# LargeDummyDevice register map
File version: 1.0
Registers are 32-bit, read-write, no defined reset value unless marked. A register's access mark holds for its fields unless they carry their own. Offsets are from the block's base; [hi:lo] are bit positions.

## PERIPHERAL_63
Base 0x4003E000
0x04 REG_1 — Register 1
  [29] FIELD_5, [29:28] FIELD_1, [22] FIELD_2, [17] FIELD_6, [14:10] FIELD_4, [9] FIELD_3
0x08 REG_2 — Register 2
  [32:31] FIELD_25, [30] FIELD_13, [29:27] FIELD_14, [27:26] FIELD_9, [29:26] FIELD_10, [25] FIELD_22, [24] FIELD_2, [27:24] FIELD_5, [28:24] FIELD_12, [25:24] FIELD_24, [24:23] FIELD_18, [22:21] FIELD_7, [25:21] FIELD_8, [25:21] FIELD_15, [22:21] FIELD_23, [21:19] FIELD_21, [18] FIELD_29, [19:18] FIELD_32, [20:16] FIELD_3, [18:16] FIELD_17, [19:15] FIELD_11, [12] FIELD_4, [12] FIELD_19, [11] FIELD_16, [12:11] FIELD_26, [13:10] FIELD_30, [13:10] FIELD_31, [11:7] FIELD_27, [10:6] FIELD_20, [9:5] FIELD_28, [8:4] FIELD_1, [4:0] FIELD_6
0x0C REG_3 — Register 3
  [30:29] FIELD_4, [33:29] FIELD_12, [24] FIELD_2, [21:19] FIELD_5, [20:19] FIELD_15, [18:17] FIELD_9, [19:15] FIELD_8, [18:14] FIELD_13, [17:13] FIELD_14, [13:9] FIELD_10, [8:7] FIELD_3, [9:6] FIELD_1, [7:5] FIELD_11, [3:2] FIELD_6, [4:1] FIELD_7
0x10 REG_4 — Register 4
  [25] FIELD_1, [23] FIELD_2, [16:13] FIELD_3, [6] FIELD_5, [7:3] FIELD_4
0x14 REG_5 — Register 5
  [26:25] FIELD_14, [19] FIELD_3, [21:17] FIELD_5, [16] FIELD_15, [17:15] FIELD_8, [15:14] FIELD_10, [15:14] FIELD_13, [15:11] FIELD_2, [14:10] FIELD_4, [12:10] FIELD_6, [14:10] FIELD_7, [8:7] FIELD_16, [8:4] FIELD_12, [5:3] FIELD_9, [4:1] FIELD_11, [3:0] FIELD_1
0x18 REG_6 — Register 6
  [29] FIELD_13, [29:27] FIELD_8, [27:26] FIELD_6, [28:25] FIELD_11, [25:24] FIELD_1, [21:20] FIELD_9, [18:14] FIELD_2, [6] FIELD_3, [9:6] FIELD_5, [6:4] FIELD_10, [6:4] FIELD_12, [5:3] FIELD_15, [6:2] FIELD_7, [3:1] FIELD_4, [2:0] FIELD_14
0x1C REG_7 — Register 7
  [32:31] FIELD_22, [34:30] FIELD_6, [32:30] FIELD_25, [28:25] FIELD_15, [28:24] FIELD_27, [26:23] FIELD_18, [25:23] FIELD_19, [24:22] FIELD_4, [23:20] FIELD_10, [20:18] FIELD_11, [18] FIELD_20, [18:17] FIELD_5, [17] FIELD_28, [18:14] FIELD_1, [16:14] FIELD_2, [16:13] FIELD_3, [12] FIELD_12, [15:12] FIELD_24, [14:12] FIELD_26, [13:11] FIELD_8, [14:10] FIELD_14, [13:10] FIELD_21, [7] FIELD_7, [6] FIELD_9, [8:6] FIELD_29, [9:5] FIELD_17, [4:2] FIELD_13, [2] FIELD_23, [4:2] FIELD_30, [3:0] FIELD_16
0x20 REG_8 — Register 8
  [35:31] FIELD_6, [31:29] FIELD_4, [32:28] FIELD_9, [25] FIELD_20, [26:24] FIELD_18, [20] FIELD_3, [19:18] FIELD_5, [20:18] FIELD_8, [18] FIELD_17, [19:15] FIELD_16, [12:11] FIELD_11, [13:11] FIELD_21, [12:10] FIELD_2, [8:7] FIELD_14, [10:6] FIELD_12, [7:6] FIELD_13, [4] FIELD_19, [5:3] FIELD_10, [2] FIELD_15, [0] FIELD_1, [3:0] FIELD_7
0x24 REG_9 — Register 9
  [35:31] FIELD_3, [29:26] FIELD_13, [28:24] FIELD_14, [19:18] FIELD_11, [13] FIELD_15, [13:11] FIELD_2, [11:10] FIELD_8, [10:9] FIELD_5, [12:8] FIELD_4, [10:6] FIELD_9, [8:4] FIELD_12, [4:3] FIELD_1, [7:3] FIELD_6, [5:3] FIELD_10, [3:0] FIELD_7
0x28 REG_10 — Register 10
  [29:28] FIELD_9, [21] FIELD_7, [25:21] FIELD_10, [20:18] FIELD_6, [20:17] FIELD_3, [15:13] FIELD_2, [14:12] FIELD_11, [12:11] FIELD_1, [7] FIELD_4, [4:3] FIELD_5, [2] FIELD_8
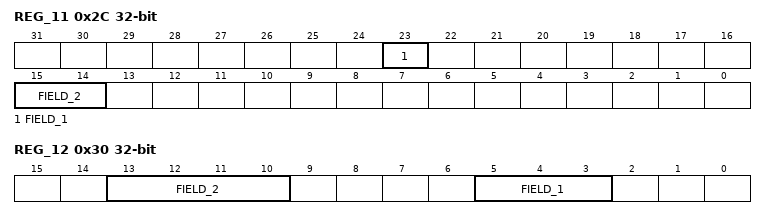
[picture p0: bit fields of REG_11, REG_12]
0x2C REG_11 — Register 11
  [23] FIELD_1, [15:14] FIELD_2
0x30 REG_12 — Register 12
  [13:10] FIELD_2, [5:3] FIELD_1
0x34 REG_13 — Register 13
  [31] FIELD_3, [32:30] FIELD_5, [31:28] FIELD_18, [30:28] FIELD_30, [27] FIELD_8, [28:26] FIELD_7, [29:25] FIELD_29, [25:23] FIELD_24, [23] FIELD_31, [23:22] FIELD_25, [23:20] FIELD_28, [21:19] FIELD_11, [22:19] FIELD_22, [18] FIELD_10, [17] FIELD_2, [17] FIELD_17, [19:17] FIELD_19, [21:17] FIELD_21, [18:16] FIELD_9, [16] FIELD_13, [16] FIELD_15, [18:15] FIELD_12, [16:14] FIELD_1, [15:11] FIELD_6, [10:9] FIELD_23, [9:7] FIELD_26, [7:6] FIELD_4, [7:6] FIELD_16, [6:2] FIELD_14, [3:2] FIELD_20, [3:1] FIELD_27
0x38 REG_14 — Register 14
  [32:30] FIELD_5, [32:30] FIELD_20, [33:29] FIELD_6, [30:28] FIELD_9, [28:27] FIELD_3, [28:27] FIELD_7, [29:25] FIELD_11, [27:23] FIELD_16, [23:22] FIELD_2, [21] FIELD_13, [20] FIELD_8, [24:20] FIELD_14, [22:18] FIELD_10, [18:17] FIELD_1, [19:15] FIELD_19, [15:13] FIELD_15, [11] FIELD_18, [8] FIELD_12, [3:2] FIELD_4, [4:1] FIELD_17
0x3C REG_15 — Register 15
  [29] FIELD_28, [30:26] FIELD_29, [26:25] FIELD_11, [28:24] FIELD_23, [25:23] FIELD_7, [22:18] FIELD_8, [21:18] FIELD_20, [18] FIELD_24, [21:17] FIELD_31, [18:15] FIELD_12, [18:14] FIELD_1, [17:14] FIELD_18, [15:12] FIELD_17, [14:11] FIELD_10, [14:11] FIELD_32, [14:10] FIELD_30, [12:9] FIELD_15, [10:9] FIELD_21, [10:9] FIELD_26, [13:9] FIELD_27, [12:8] FIELD_3, [8] FIELD_9, [9:7] FIELD_2, [7] FIELD_4, [9:7] FIELD_6, [10:7] FIELD_22, [6:5] FIELD_5, [5:4] FIELD_13, [6:2] FIELD_16, [2] FIELD_25, [2:1] FIELD_14, [4:0] FIELD_19
0x40 REG_16 — Register 16
  [34:30] FIELD_17, [32:28] FIELD_10, [28:25] FIELD_6, [29:25] FIELD_7, [25:24] FIELD_2, [19:18] FIELD_3, [19:17] FIELD_9, [16:15] FIELD_13, [15] FIELD_20, [15:14] FIELD_5, [18:14] FIELD_16, [16:13] FIELD_1, [16:13] FIELD_21, [12] FIELD_18, [14:11] FIELD_19, [10] FIELD_8, [11:9] FIELD_4, [11:8] FIELD_12, [3:2] FIELD_11, [2] FIELD_22, [1] FIELD_14, [3:1] FIELD_15
0x44 REG_17 — Register 17
  [34:31] FIELD_1, [33:29] FIELD_2, [32:29] FIELD_10, [26] FIELD_8, [26] FIELD_13, [25:24] FIELD_14, [28:24] FIELD_16, [28:24] FIELD_18, [24:23] FIELD_4, [25:22] FIELD_9, [19:16] FIELD_12, [12] FIELD_15, [13:10] FIELD_21, [9] FIELD_7, [10:9] FIELD_17, [10:9] FIELD_20, [6] FIELD_3, [7:4] FIELD_6, [8:4] FIELD_19, [1] FIELD_11, [0] FIELD_5
0x48 REG_18 — Register 18
  [32:31] FIELD_9, [26] FIELD_10, [27:23] FIELD_2, [23:20] FIELD_7, [17] FIELD_5, [15:13] FIELD_3, [11:9] FIELD_6, [4:3] FIELD_8, [4:2] FIELD_4, [3:0] FIELD_1
0x4C REG_19 — Register 19
  [33:29] FIELD_9, [30:29] FIELD_20, [29:26] FIELD_1, [26] FIELD_4, [28:25] FIELD_10, [25:24] FIELD_11, [25:22] FIELD_12, [22] FIELD_15, [19:18] FIELD_18, [16:15] FIELD_7, [18:14] FIELD_3, [13:12] FIELD_17, [13:9] FIELD_2, [12:8] FIELD_5, [10:8] FIELD_8, [10:6] FIELD_19, [7:5] FIELD_16, [7:3] FIELD_13, [3:2] FIELD_14, [2:0] FIELD_6
0x50 REG_20 — Register 20
  [34:31] FIELD_14, [31] FIELD_18, [32:30] FIELD_10, [29] FIELD_12, [31:29] FIELD_13, [29] FIELD_20, [30:28] FIELD_5, [31:28] FIELD_6, [32:28] FIELD_24, [28] FIELD_29, [30:26] FIELD_8, [27:26] FIELD_22, [29:25] FIELD_16, [27:23] FIELD_19, [23] FIELD_25, [20] FIELD_2, [19] FIELD_26, [19:16] FIELD_4, [17:16] FIELD_30, [18:14] FIELD_17, [16:14] FIELD_28, [12] FIELD_11, [12:11] FIELD_1, [11:10] FIELD_9, [9:7] FIELD_23, [6] FIELD_3, [8:4] FIELD_21, [4] FIELD_27, [3] FIELD_15, [1] FIELD_7
0x54 REG_21 — Register 21
  [31:29] FIELD_20, [32:28] FIELD_28, [29:26] FIELD_1, [29:25] FIELD_23, [26:24] FIELD_11, [24] FIELD_14, [27:23] FIELD_15, [21] FIELD_5, [21] FIELD_12, [22:21] FIELD_16, [24:20] FIELD_24, [18:16] FIELD_27, [17:15] FIELD_18, [17:14] FIELD_22, [14] FIELD_25, [14:13] FIELD_19, [15:12] FIELD_21, [12:10] FIELD_2, [12:10] FIELD_8, [9:7] FIELD_26, [8:5] FIELD_3, [8:4] FIELD_4, [6:2] FIELD_9, [1] FIELD_6, [5:1] FIELD_17, [2:0] FIELD_7, [0] FIELD_10, [2:0] FIELD_13
0x58 REG_22 — Register 22
  [32:31] FIELD_1, [31] FIELD_4, [31:29] FIELD_17, [28] FIELD_18, [27:25] FIELD_2, [26:25] FIELD_8, [28:24] FIELD_9, [24:20] FIELD_11, [17:16] FIELD_13, [19:15] FIELD_10, [14:12] FIELD_3, [12] FIELD_15, [15:11] FIELD_7, [10] FIELD_14, [12:10] FIELD_19, [9] FIELD_12, [9:5] FIELD_6, [6:3] FIELD_16, [5:1] FIELD_5
0x5C REG_23 — Register 23
  [31:30] FIELD_6, [31:30] FIELD_12, [31:29] FIELD_16, [25] FIELD_2, [25:24] FIELD_3, [23:21] FIELD_5, [20:19] FIELD_13, [19:18] FIELD_15, [14:10] FIELD_1, [13:10] FIELD_11, [12:9] FIELD_9, [11:9] FIELD_10, [8:6] FIELD_14, [2] FIELD_7, [2] FIELD_8, [2:1] FIELD_4
0x60 REG_24 — Register 24
  [32:31] FIELD_15, [33:29] FIELD_14, [27:26] FIELD_10, [25:23] FIELD_8, [22:21] FIELD_11, [21:20] FIELD_3, [23:19] FIELD_9, [17] FIELD_4, [16:13] FIELD_7, [13:9] FIELD_1, [10:8] FIELD_5, [9:6] FIELD_2, [5] FIELD_12, [8:4] FIELD_13, [3] FIELD_6
0x64 REG_25 — Register 25
  [34:30] FIELD_5, [31:30] FIELD_11, [34:30] FIELD_12, [29:28] FIELD_18, [31:28] FIELD_21, [31:27] FIELD_16, [28:26] FIELD_6, [22] FIELD_8, [26:22] FIELD_14, [23:22] FIELD_23, [22:20] FIELD_24, [20:19] FIELD_7, [21:17] FIELD_13, [17:15] FIELD_9, [14] FIELD_19, [14:10] FIELD_3, [13:9] FIELD_20, [9:8] FIELD_4, [5:4] FIELD_2, [8:4] FIELD_10, [8:4] FIELD_15, [5:4] FIELD_17, [6:3] FIELD_25, [1] FIELD_1, [2:1] FIELD_22
0x68 REG_26 — Register 26
  [29:28] FIELD_1, [32:28] FIELD_4, [30:27] FIELD_16, [29:26] FIELD_7, [28:26] FIELD_9, [24:21] FIELD_2, [24:21] FIELD_19, [22:21] FIELD_24, [20:19] FIELD_10, [21:19] FIELD_14, [17] FIELD_11, [17] FIELD_12, [15] FIELD_18, [19:15] FIELD_21, [19:15] FIELD_25, [17:14] FIELD_8, [16:12] FIELD_3, [13:11] FIELD_15, [14:10] FIELD_5, [11:10] FIELD_13, [13:10] FIELD_23, [10:6] FIELD_17, [5:3] FIELD_6, [7:3] FIELD_22, [3:0] FIELD_20
0x6C REG_27 — Register 27
  [30] FIELD_21, [31:29] FIELD_1, [33:29] FIELD_7, [29:28] FIELD_2, [29:28] FIELD_9, [27] FIELD_3, [29:27] FIELD_25, [29:26] FIELD_5, [23:22] FIELD_8, [24:22] FIELD_11, [25:22] FIELD_18, [24:21] FIELD_27, [23:20] FIELD_12, [21:20] FIELD_20, [20:18] FIELD_22, [20:17] FIELD_16, [17:16] FIELD_14, [20:16] FIELD_23, [17:14] FIELD_6, [16:14] FIELD_13, [17:14] FIELD_15, [15:12] FIELD_24, [7] FIELD_19, [9:6] FIELD_26, [3] FIELD_10, [4:1] FIELD_17, [1:0] FIELD_4
0x70 REG_28 — Register 28
  [32:31] FIELD_9, [34:30] FIELD_12, [33:29] FIELD_17, [28] FIELD_15, [24] FIELD_7, [23] FIELD_16, [24:21] FIELD_6, [19:18] FIELD_2, [20:17] FIELD_8, [20:16] FIELD_4, [16] FIELD_14, [15:11] FIELD_13, [8:5] FIELD_1, [7:5] FIELD_10, [4:3] FIELD_3, [7:3] FIELD_5, [3:0] FIELD_11
0x74 REG_29 — Register 29
  [31] FIELD_5, [33:31] FIELD_7, [30:29] FIELD_22, [28] FIELD_25, [27:26] FIELD_21, [26:24] FIELD_9, [25:24] FIELD_14, [27:24] FIELD_27, [26:23] FIELD_18, [25:22] FIELD_3, [22] FIELD_17, [23:22] FIELD_28, [22:21] FIELD_15, [17] FIELD_11, [18:17] FIELD_24, [17:16] FIELD_16, [15:13] FIELD_8, [15:13] FIELD_20, [13:11] FIELD_13, [11:10] FIELD_19, [11:9] FIELD_10, [11:8] FIELD_29, [7:6] FIELD_4, [8:6] FIELD_6, [8:5] FIELD_26, [7:3] FIELD_1, [2] FIELD_12, [4:2] FIELD_23, [4:1] FIELD_30, [4:0] FIELD_2
0x78 REG_30 — Register 30
  [31:30] FIELD_3, [31:30] FIELD_6, [32:30] FIELD_8, [33:30] FIELD_18, [32:29] FIELD_25, [24] FIELD_20, [25:23] FIELD_7, [26:22] FIELD_9, [23:22] FIELD_16, [23:22] FIELD_17, [23:21] FIELD_12, [21] FIELD_15, [20:19] FIELD_2, [19:18] FIELD_26, [20:17] FIELD_27, [20:16] FIELD_19, [15] FIELD_1, [13] FIELD_4, [13:12] FIELD_29, [10] FIELD_23, [9] FIELD_13, [13:9] FIELD_14, [10:8] FIELD_22, [11:8] FIELD_28, [11:7] FIELD_5, [6] FIELD_24, [4:3] FIELD_30, [6:2] FIELD_11, [4:2] FIELD_21, [3:0] FIELD_10
0x7C REG_31 — Register 31
  [34:30] FIELD_19, [29] FIELD_9, [32:29] FIELD_13, [26] FIELD_3, [21:20] FIELD_2, [20] FIELD_18, [20:17] FIELD_4, [16] FIELD_8, [13] FIELD_11, [15:13] FIELD_15, [16:13] FIELD_20, [16:12] FIELD_10, [13:12] FIELD_14, [14:12] FIELD_17, [9:8] FIELD_6, [11:7] FIELD_1, [5:4] FIELD_16, [4:2] FIELD_5, [5:2] FIELD_7, [4:1] FIELD_12
0x80 REG_32 — Register 32
  [31] FIELD_4, [33:31] FIELD_10, [28] FIELD_3, [31:27] FIELD_13, [25] FIELD_1, [28:25] FIELD_2, [28:25] FIELD_7, [22:21] FIELD_14, [21:20] FIELD_5, [23:19] FIELD_12, [15:14] FIELD_8, [11] FIELD_6, [15:11] FIELD_11, [8:5] FIELD_9
0x84 REG_33 — Register 33
  [33:30] FIELD_13, [29] FIELD_9, [31:28] FIELD_15, [29:27] FIELD_2, [30:26] FIELD_10, [28:25] FIELD_7, [26:24] FIELD_8, [25:21] FIELD_18, [21:20] FIELD_4, [16] FIELD_12, [17:15] FIELD_11, [14:11] FIELD_14, [12:9] FIELD_16, [8:6] FIELD_20, [3:2] FIELD_3, [5:2] FIELD_5, [4:1] FIELD_1, [1] FIELD_17, [4:1] FIELD_19, [0] FIELD_6
0x88 REG_34 — Register 34
  [31:30] FIELD_10, [26] FIELD_8, [27:24] FIELD_5, [27:24] FIELD_7, [20] FIELD_3, [23:20] FIELD_4, [20:17] FIELD_6, [17:13] FIELD_12, [15:12] FIELD_1, [14:11] FIELD_13, [10] FIELD_9, [12:10] FIELD_15, [6] FIELD_11, [8:4] FIELD_2, [6:3] FIELD_14
0x8C REG_35 — Register 35
  [32:31] FIELD_8, [34:31] FIELD_19, [34:31] FIELD_21, [35:31] FIELD_30, [33:29] FIELD_15, [29:28] FIELD_1, [29:28] FIELD_4, [30:28] FIELD_20, [26] FIELD_3, [26:25] FIELD_22, [24:22] FIELD_7, [23:22] FIELD_9, [23:20] FIELD_27, [22:19] FIELD_29, [22:18] FIELD_25, [15] FIELD_16, [12] FIELD_6, [15:12] FIELD_18, [13:12] FIELD_23, [12:11] FIELD_24, [9] FIELD_12, [11:8] FIELD_11, [9:5] FIELD_13, [9:5] FIELD_26, [8:4] FIELD_2, [5:4] FIELD_17, [4:2] FIELD_10, [3:2] FIELD_14, [4:1] FIELD_5, [4:0] FIELD_28
0x90 REG_36 — Register 36
  [31] FIELD_4, [35:31] FIELD_6, [33:30] FIELD_5, [32:29] FIELD_13, [33:29] FIELD_18, [30:28] FIELD_15, [26:22] FIELD_10, [24:20] FIELD_2, [22:18] FIELD_27, [17:16] FIELD_21, [17:15] FIELD_3, [15:13] FIELD_8, [17:13] FIELD_19, [13:11] FIELD_12, [12:10] FIELD_16, [11:10] FIELD_22, [14:10] FIELD_24, [13:10] FIELD_25, [11:9] FIELD_17, [11:8] FIELD_7, [8] FIELD_11, [10:8] FIELD_20, [11:7] FIELD_14, [7:6] FIELD_1, [6] FIELD_23, [3] FIELD_26, [3:0] FIELD_9
0x94 REG_37 — Register 37
  [33:31] FIELD_18, [32:28] FIELD_10, [28] FIELD_21, [30:28] FIELD_23, [27:26] FIELD_1, [30:26] FIELD_11, [26:24] FIELD_4, [27:24] FIELD_20, [22:21] FIELD_16, [21:19] FIELD_3, [16:14] FIELD_8, [16:12] FIELD_5, [12:10] FIELD_2, [14:10] FIELD_13, [9] FIELD_25, [11:8] FIELD_24, [7:6] FIELD_6, [8:6] FIELD_7, [6] FIELD_9, [6:5] FIELD_14, [8:5] FIELD_22, [7:4] FIELD_19, [5:2] FIELD_17, [4:1] FIELD_15, [2:0] FIELD_12
0x98 REG_38 — Register 38
  [32:29] FIELD_8, [31:28] FIELD_5, [28] FIELD_19, [27] FIELD_21, [26] FIELD_14, [30:26] FIELD_17, [26:24] FIELD_2, [24:23] FIELD_7, [26:23] FIELD_11, [27:23] FIELD_12, [25:23] FIELD_15, [24:21] FIELD_1, [16:15] FIELD_22, [18:14] FIELD_6, [14] FIELD_16, [14:12] FIELD_20, [15:11] FIELD_10, [12:9] FIELD_18, [11:7] FIELD_9, [8:5] FIELD_3, [5:3] FIELD_4, [1:0] FIELD_13
0x9C REG_39 — Register 39
  [31] FIELD_10, [30:28] FIELD_9, [27:25] FIELD_5, [24:23] FIELD_4, [14:13] FIELD_6, [14:10] FIELD_8, [8:7] FIELD_1, [10:7] FIELD_7, [6:5] FIELD_3, [2] FIELD_2
